# EOS-S3 register map
File version: 0.1
CPU: CM4 r0p1, selectable endian, MPU, FPU, 3 interrupt priority bits
Registers are 32-bit, read-write, reset 0x0 unless marked. A register's access mark holds for its fields unless they carry their own. Offsets are from the block's base; [hi:lo] are bit positions; {n}, {i} and the like mark numbered series; 'fields as' and 'values as' point back to an identical list.

## INTR_CTRL — Interrupt Controller
Base 0x40004800
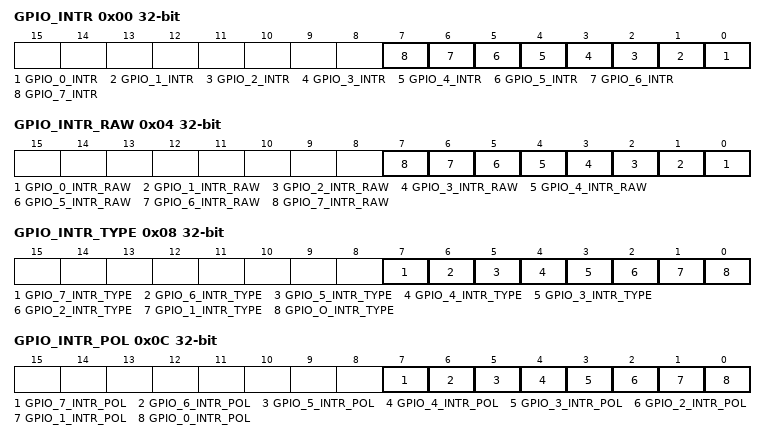
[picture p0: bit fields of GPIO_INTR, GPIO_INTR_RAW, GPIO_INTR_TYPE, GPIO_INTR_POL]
0x00 GPIO_INTR — Indicators of interrupt triggers detected
  [n] GPIO_{n}_INTR (n=0..7) — Active high edge interrupt detected for GPIO_{n}. When interrupt type is selected as edge detect, this register will return high when triggered, write 1 to clear.
0x04 GPIO_INTR_RAW — GPIO raw interrupt indicators
  [n] GPIO_{n}_INTR_RAW ro (n=0..7) — Raw interrupt for GPIO_{n}. This register will reflect the value of the IO regardless of the type/polarity
0x08 GPIO_INTR_TYPE — Indicators of interrupt trigger types
  [all] fields
    0=level (Interrupt is triggered by a certain level (High or Low)); 1=edge (Interrupt is triggered by a signal edge (Falling or Rising))
  [7] GPIO_7_INTR_TYPE — GPIO_7 interrupt type {0: level, 1: edge}
  [6] GPIO_6_INTR_TYPE — GPIO_6 interrupt type {0: level, 1: edge}
  [5] GPIO_5_INTR_TYPE — GPIO_5 interrupt type {0: level, 1: edge}
  [4] GPIO_4_INTR_TYPE — GPIO_4 interrupt type {0: level, 1: edge}
  [3] GPIO_3_INTR_TYPE — GPIO_3 interrupt type {0: level, 1: edge}
  [2] GPIO_2_INTR_TYPE — GPIO_2 interrupt type {0: level, 1: edge}
  [1] GPIO_1_INTR_TYPE — GPIO_1 interrupt type {0: level, 1: edge}
  [0] GPIO_O_INTR_TYPE — GPIO_0 interrupt type {0: level, 1: edge}
0x0C GPIO_INTR_POL — Indicators of interrupt trigger polarities (will depend on the type of interrupt)
  [all] fields
    0=low_fall (Depending on the type, if the interrupt is triggered by level, this indicates the interrupt is triggered by a reading low value, if it is an edge trigger, this value indicates that the interrupt polarity is falling edge); 1=high_rise (Depending on the type, if the interrupt is triggered by level, this indicates the interrupt is triggered by a reading high value, if it is an edge trigger, this value indicates that the interrupt polarity is rising edge)
  [7] GPIO_7_INTR_POL — GPIO_7 interrupt polarity (depends on interrupt type): type = level => {0:low, 1:hi} --- type = edge => {0:fall, 1:rise}
  [6] GPIO_6_INTR_POL — GPIO_6 interrupt polarity (depends on interrupt type): type = level => {0:low, 1:hi} --- type = edge => {0:fall, 1:rise}
  [5] GPIO_5_INTR_POL — GPIO_5 interrupt polarity (depends on interrupt type): type = level => {0:low, 1:hi} --- type = edge => {0:fall, 1:rise}
  [4] GPIO_4_INTR_POL — GPIO_4 interrupt polarity (depends on interrupt type): type = level => {0:low, 1:hi} --- type = edge => {0:fall, 1:rise}
  [3] GPIO_3_INTR_POL — GPIO_3 interrupt polarity (depends on interrupt type): type = level => {0:low, 1:hi} --- type = edge => {0:fall, 1:rise}
  [2] GPIO_2_INTR_POL — GPIO_2 interrupt polarity (depends on interrupt type): type = level => {0:low, 1:hi} --- type = edge => {0:fall, 1:rise}
  [1] GPIO_1_INTR_POL — GPIO_1 interrupt polarity (depends on interrupt type): type = level => {0:low, 1:hi} --- type = edge => {0:fall, 1:rise}
  [0] GPIO_0_INTR_POL — GPIO_0 interrupt polarity (depends on interrupt type): type = level => {0:low, 1:hi} --- type = edge => {0:fall, 1:rise}
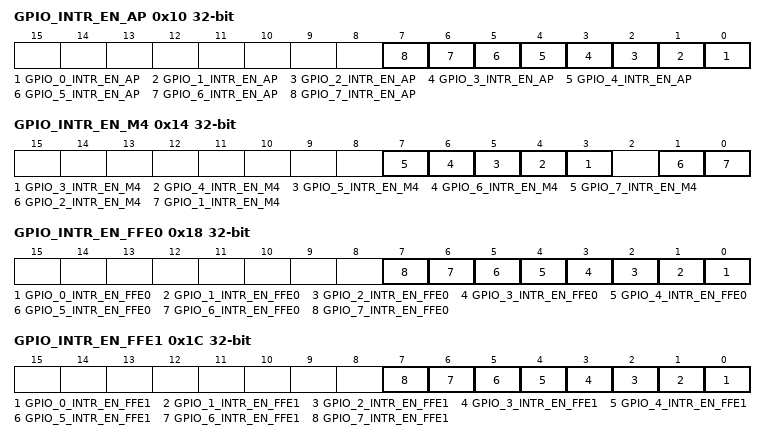
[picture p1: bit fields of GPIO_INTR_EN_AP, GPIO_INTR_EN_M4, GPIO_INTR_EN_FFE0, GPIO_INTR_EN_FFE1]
0x10 GPIO_INTR_EN_AP — GPIO interrupt enable for AP
  [all] fields
    0=enable (Disable the interrupt for the power domain); 1=disable (Enable the interrupt for the power domain)
  [n] GPIO_{n}_INTR_EN_AP (n=0..7) — GPIO_{n} interrupt enable for AP
0x14 GPIO_INTR_EN_M4 — GPIO interrupt enable for M4
  [all] fields
    values as the fields of GPIO_INTR_EN_AP
  [n] GPIO_{n}_INTR_EN_M4 (n=3..7) — GPIO_{n} interrupt enable for M4
  [1] GPIO_2_INTR_EN_M4 — GPIO_1 interrupt enable for M4
  [0] GPIO_1_INTR_EN_M4 — GPIO_0 interrupt enable for M4
0x18 GPIO_INTR_EN_FFE0 — GPIO interrupt enable for FFE0
  [all] fields
    values as the fields of GPIO_INTR_EN_AP
  [n] GPIO_{n}_INTR_EN_FFE0 (n=0..7) — GPIO_{n} interrupt enable for FFE0
0x1C GPIO_INTR_EN_FFE1 — GPIO interrupt enable for FFE1
  [all] fields
    values as the fields of GPIO_INTR_EN_AP
  [n] GPIO_{n}_INTR_EN_FFE1 (n=0..7) — GPIO_{n} interrupt enable for FFE1
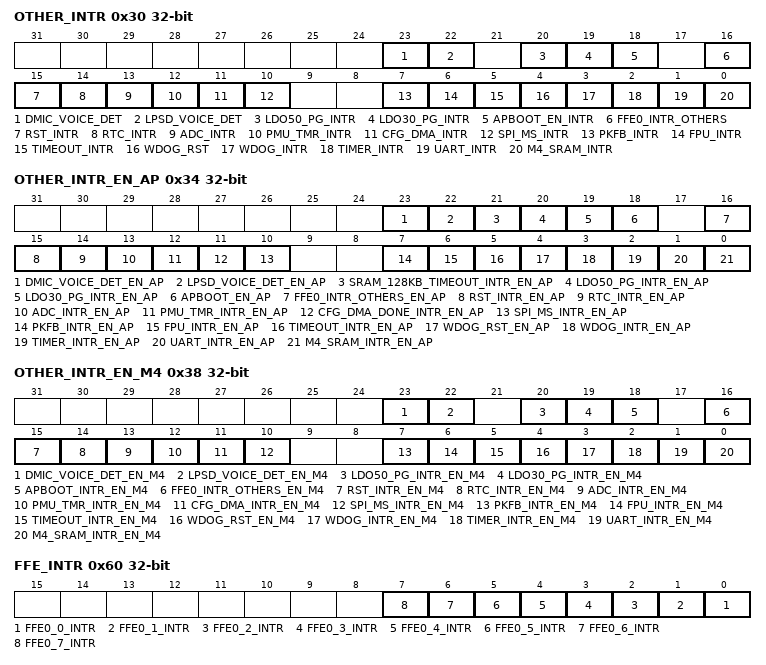
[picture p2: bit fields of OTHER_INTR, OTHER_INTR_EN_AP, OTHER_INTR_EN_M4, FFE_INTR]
0x30 OTHER_INTR (reset mask 0xFF) — Indicators of interrupt triggers detected
  [23] DMIC_VOICE_DET — Interrupt detected for Digital MIC
  [22] LPSD_VOICE_DET — Interrupt detected for LPSD Voice
  [20] LDO50_PG_INTR — Interrupt detected for absence of LDO30 power good
  [19] LDO30_PG_INTR — Interrupt detected for absence of LDO30 power good
  [18] APBOOT_EN_INTR — Interrupt detected for AP boot
  [16] FFE0_INTR_OTHERS — Interrupt detected for FFE0 other interrupts
  [15] RST_INTR — Interrupt detected for Reset
  [14] RTC_INTR — Interrupt detected for RTC
  [13] ADC_INTR — Interrupt detected for ADC
  [12] PMU_TMR_INTR — Interrupt detected for PMU Timer
  [11] CFG_DMA_INTR — Interrupt detected for Config DMA
  [10] SPI_MS_INTR — Interrupt detected for SPI Master
  [7] PKFB_INTR — Interrupt detected for Packet FIFO Bank
  [6] FPU_INTR — Interrupt detected for M4 FPU
  [5] TIMEOUT_INTR — Interrupt detected for bus timeout
  [4] WDOG_RST — Interrupt detected for WDT M4 Reset
  [3] WDOG_INTR — Interrupt detected for WDT M4
  [2] TIMER_INTR — Interrupt detected for timer
  [1] UART_INTR — Interrupt detected for UART
  [0] M4_SRAM_INTR — Interrupt detected for M4 SRAM (access during low power)
0x34 OTHER_INTR_EN_AP (reset mask 0xFF) — Various interrupt enable for AP
  [all] fields
    values as the fields of GPIO_INTR_EN_AP
  [23] DMIC_VOICE_DET_EN_AP — Digital Mic interrupt enable for AP
  [22] LPSD_VOICE_DET_EN_AP — LPSD Voice detected interrupt enable for AP
  [21] SRAM_128KB_TIMEOUT_INTR_EN_AP — SRAM_128KB_TIMEOUT interrupt enable for AP
  [20] LDO50_PG_INTR_EN_AP — LDO50 absence of power good interrupt enable for AP
  [19] LDO30_PG_INTR_EN_AP — LDO30 absence of power good interrupt enable for AP
  [18] APBOOT_EN_AP — AP Boot interrupt enable for AP
  [16] FFE0_INTR_OTHERS_EN_AP — FFE0 Other interrupt enable for AP
  [15] RST_INTR_EN_AP — Reset interrupt enable for AP
  [14] RTC_INTR_EN_AP — RTC interrupt enable for AP
  [13] ADC_INTR_EN_AP — ADC interrupt enable for AP
  [12] PMU_TMR_INTR_EN_AP — PMU Timer interrupt enable for AP
  [11] CFG_DMA_DONE_INTR_EN_AP — Config DMA interrupt enable for AP
  [10] SPI_MS_INTR_EN_AP — SPI Master interrupt enable for AP
  [7] PKFB_INTR_EN_AP — Packet FIFO Bank interrupt enable for AP
  [6] FPU_INTR_EN_AP — M4 FPU interrupt enable for AP
  [5] TIMEOUT_INTR_EN_AP — Bus Timeout interrupt enable for AP
  [4] WDOG_RST_EN_AP — WDT M4 Reset interrupt enable for AP
  [3] WDOG_INTR_EN_AP — WDT M4 interrupt enable for AP
  [2] TIMER_INTR_EN_AP — Timer interrupt enable for AP
  [1] UART_INTR_EN_AP — UART interrupt enable for AP
  [0] M4_SRAM_INTR_EN_AP — M4 SRAM (access during low power) interrupt enable for AP
0x38 OTHER_INTR_EN_M4 (reset mask 0xFF) — Various interrupt enable for M4
  [all] fields
    values as the fields of GPIO_INTR_EN_AP
  [23] DMIC_VOICE_DET_EN_M4 — Digital Mic Voice detected interrupt enable for M4
  [22] LPSD_VOICE_DET_EN_M4 — LPSD Voice detected interrupt enable for M4
  [20] LDO50_PG_INTR_EN_M4 — Absence of LDO50 power good interrupt enable for M4
  [19] LDO30_PG_INTR_EN_M4 — Absence of LDO30 power good interrupt enable for M4
  [18] APBOOT_INTR_EN_M4 — AP Boot interrupt enable for M4
  [16] FFE0_INTR_OTHERS_EN_M4 — FFE0 other interrupts enable for M4
  [15] RST_INTR_EN_M4 — Reset interrupt enable for M4
  [14] RTC_INTR_EN_M4 — RTC interrupt enable for M4
  [13] ADC_INTR_EN_M4 — ADC interrupt enable for M4
  [12] PMU_TMR_INTR_EN_M4 — PMU Timer interrupt enable for M4
  [11] CFG_DMA_INTR_EN_M4 — Config DMA interrupt enable for M4
  [10] SPI_MS_INTR_EN_M4 — SPI Master interrupt enable for M4
  [7] PKFB_INTR_EN_M4 — Packet FIFO Bank interrupt enable for M4
  [6] FPU_INTR_EN_M4 — M4 FPU interrupt enable for M4
  [5] TIMEOUT_INTR_EN_M4 — bus timeout interrupt enable for M4
  [4] WDOG_RST_EN_M4 — WDOG M4 Reset interrupt enable for M4
  [3] WDOG_INTR_EN_M4 — WDOG M4 interrupt enable for M4
  [2] TIMER_INTR_EN_M4 — Timer interrupt enable for M4
  [1] UART_INTR_EN_M4 — UART interrupt enable for M4
  [0] M4_SRAM_INTR_EN_M4 — M4 SRAM (access during low power) interrupt enable for M4
0x40 SOFTWARE_INTR_1 — Indicators of General purpose software interrupt 1 triggers detected
  [0] SW_INTR_1 — Active high edge interrupt detected for Software Interrupt 1. When interrupt type is selected as edge detect, this register will return high when triggered, write 1 to clear.
0x44 SOFTWARE_INTR_1_EN_AP — General purpose Software interrupt 1 enable for AP
  [0] SW_INTR_1_EN_AP — Software interrupt 1 enable for AP
0x50 SOFTWARE_INTR_2 — Indicators of General purpose software interrupt 2 triggers detected
  [0] SW_INTR_2 — Active high edge interrupt detected for Software Interrupt 2. When interrupt type is selected as edge detect, this register will return high when triggered, write 1 to clear.
0x54 SOFTWARE_INTR_2_EN_AP — General purpose Software interrupt 2 enable for AP
  [0] SW_INTR_2_EN_AP — Software interrupt 2 enable for AP
0x58 SOFTWARE_INTR_EN_M4 — General purpose Software interrupt 2 enable for M4
  [0] SW_INTR_2_EN_M4 — Software interrupt 2 enable for M4
    values as the fields of GPIO_INTR_EN_AP
0x60 FFE_INTR — Indicators of FFE0 interrupt triggers detected
  [n] FFE0_{n}_INTR (n=0..7) — Active high edge interrupt detected for FFE0_{n}. When interrupt type is selected as edge detect, this register will return high when triggered, write 1 to clear.
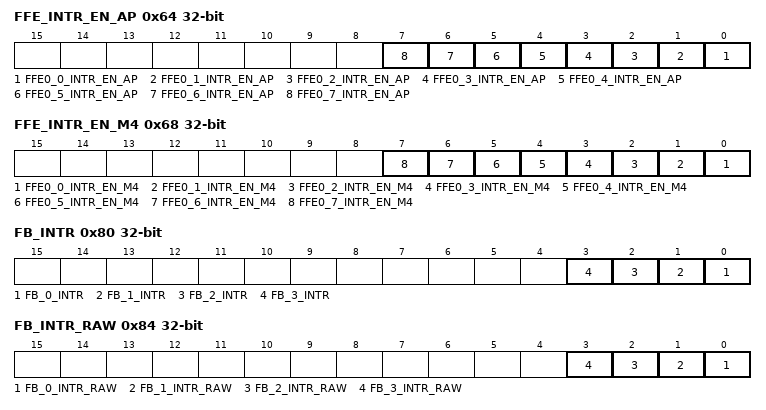
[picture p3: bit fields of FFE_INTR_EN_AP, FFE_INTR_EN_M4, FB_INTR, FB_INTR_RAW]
0x64 FFE_INTR_EN_AP — FFE0 interrupt enable for AP
  [all] fields
    values as the fields of GPIO_INTR_EN_AP
  [n] FFE0_{n}_INTR_EN_AP (n=0..7) — FFE0_{n} interrupt enable for AP
0x68 FFE_INTR_EN_M4 — FFE0 interrupt enable for M4
  [all] fields
    values as the fields of GPIO_INTR_EN_AP
  [n] FFE0_{n}_INTR_EN_M4 (n=0..7) — FFE0_{n} interrupt enable for M4
0x80 FB_INTR — Indicators of interrupt triggers detected
  [n] FB_{n}_INTR (n=0..3) — Active high edge interrupt detected for Fabric. When interrupt type is selected as edge detect, this register will return high when triggered, write 1 to clear.
0x84 FB_INTR_RAW — FB raw interrupt indicators
  [n] FB_{n}_INTR_RAW ro (n=0..3) — Raw interrupt for Fabric. This register will reflect the value of the Fabric regardless of the type/polarity
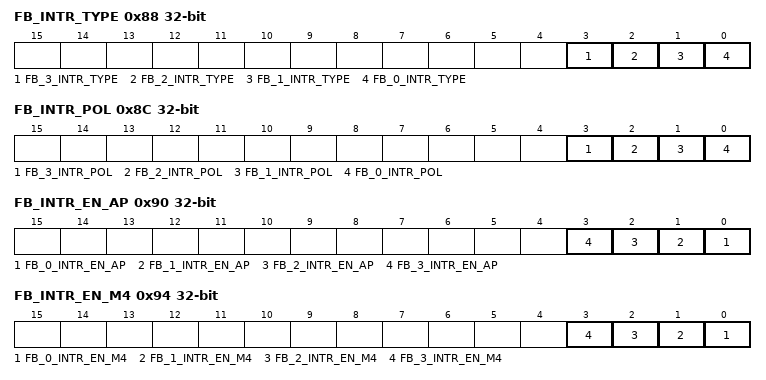
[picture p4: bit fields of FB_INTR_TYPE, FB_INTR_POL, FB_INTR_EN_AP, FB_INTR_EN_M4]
0x88 FB_INTR_TYPE — Indicators of interrupt trigger types
  [all] fields
    values as the fields of GPIO_INTR_TYPE
  [3] FB_3_INTR_TYPE — FB_3 interrupt type {0: level, 1: edge}
  [2] FB_2_INTR_TYPE — FB_2 interrupt type {0: level, 1: edge}
  [1] FB_1_INTR_TYPE — FB_1 interrupt type {0: level, 1: edge}
  [0] FB_0_INTR_TYPE — FB_0 interrupt type {0: level, 1: edge}
0x8C FB_INTR_POL — Indicators of interrupt trigger polarities (will depend on the type of interrupt)
  [all] fields
    values as the fields of GPIO_INTR_POL
  [3] FB_3_INTR_POL — FB_3 interrupt polarity (depends on interrupt type): type = level => {0:low, 1:hi} --- type = edge => {0:fall, 1:rise}
  [2] FB_2_INTR_POL — FB_2 interrupt polarity (depends on interrupt type): type = level => {0:low, 1:hi} --- type = edge => {0:fall, 1:rise}
  [1] FB_1_INTR_POL — FB_1 interrupt polarity (depends on interrupt type): type = level => {0:low, 1:hi} --- type = edge => {0:fall, 1:rise}
  [0] FB_0_INTR_POL — FB_0 interrupt polarity (depends on interrupt type): type = level => {0:low, 1:hi} --- type = edge => {0:fall, 1:rise}
0x90 FB_INTR_EN_AP — FB interrupt enable for AP
  [all] fields
    values as the fields of GPIO_INTR_EN_AP
  [n] FB_{n}_INTR_EN_AP (n=0..3) — FB_{n} interrupt enable for AP
0x94 FB_INTR_EN_M4 — FB interrupt enable for M4
  [all] fields
    values as the fields of GPIO_INTR_EN_AP
  [n] FB_{n}_INTR_EN_M4 (n=0..3) — FB_{n} interrupt enable for M4
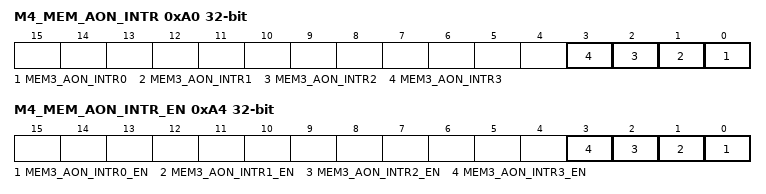
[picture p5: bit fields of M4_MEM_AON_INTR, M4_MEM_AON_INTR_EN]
0xA0 M4_MEM_AON_INTR — Indicator of detected SRAM access while shut down or sleep mode interrupts
  [n] MEM3_AON_INTR{n} (n=0..3) — Interrupt caused by a SRAM access (M4 SRAM segment {n} 32KB_0) while it in deep sleep or shut down mode
0xA4 M4_MEM_AON_INTR_EN — Interrupt enable for SRAM access while in shut down or deep sleep modes
  [n] MEM3_AON_INTR{n}_EN (n=0..3) — Interrupt enable (M4 SRAM segment {n} 32KB_0)
